# STM32H743 register map
File version: 2.4
CPU: CM7 r0p1, little endian, MPU, FPU, 4 interrupt priority bits
Registers are 32-bit, read-write, reset 0x0 unless marked. A register's access mark holds for its fields unless they carry their own. Offsets are from the block's base; [hi:lo] are bit positions; {n}, {i} and the like mark numbered series; 'fields as' and 'values as' point back to an identical list.

## HRTIM_TIMC — 高分辨率定时器：TIMC
Base 0x40017580
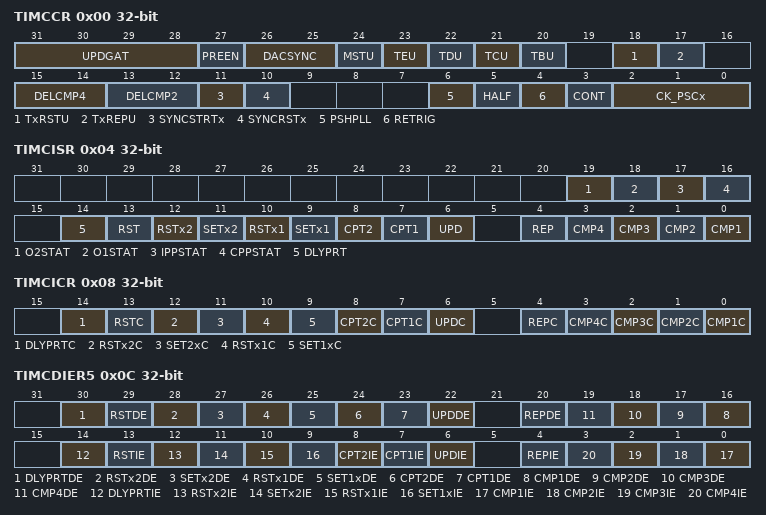
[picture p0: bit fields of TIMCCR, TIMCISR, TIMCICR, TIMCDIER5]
0x00 TIMCCR — TIMC 控制寄存器
  [31:28] UPDGAT — 更新门控
  [27] PREEN — 预装载使能
  [26:25] DACSYNC — DAC 同步
  [24] MSTU — 主定时器更新
  [23] TEU — 定时器 E 更新
  [22] TDU — 定时器 D 更新
  [21] TCU — 定时器 C 更新
  [20] TBU — 定时器 B 更新
  [18] TxRSTU — TIMC 复位更新
  [17] TxREPU — TIMC 重复更新
  [15:14] DELCMP4 — 延迟比较 4 模式
  [13:12] DELCMP2 — 延迟比较 2 模式
  [11] SYNCSTRTx — 同步启动 TIMC
  [10] SYNCRSTx — 同步复位 TIMC
  [6] PSHPLL — 推挽模式使能
  [5] HALF — 半模式使能
  [4] RETRIG — 可重触发模式
  [3] CONT — 连续模式
  [2:0] CK_PSCx — HRTIM TIMC 时钟预分频器
0x04 TIMCISR ro — TIMC 中断状态寄存器
  [19] O2STAT — 输出 2 状态
  [18] O1STAT — 输出 1 状态
  [17] IPPSTAT — 空闲推挽状态
  [16] CPPSTAT — 当前推挽状态
  [14] DLYPRT — 延迟保护标志
  [13] RST — 复位中断标志
  [12] RSTx2 — 输出 2 复位中断标志
  [11] SETx2 — 输出 2 置位中断标志
  [10] RSTx1 — 输出 1 复位中断标志
  [9] SETx1 — 输出 1 置位中断标志
  [8] CPT2 — 捕获 2 中断标志
  [7] CPT1 — 捕获 1 中断标志
  [6] UPD — 更新中断标志
  [4] REP — 重复中断标志
  [n-1] CMP{n} (n=1..4) — 比较 {n} 中断标志
0x08 TIMCICR wo — TIMC 中断清除寄存器
  [14] DLYPRTC — 延迟保护标志清除
  [13] RSTC — 复位中断标志清除
  [12] RSTx2C — 输出 2 复位标志清除
  [11] SET2xC — 输出 2 置位标志清除
  [10] RSTx1C — 输出 1 复位标志清除
  [9] SET1xC — 输出 1 置位标志清除
  [8] CPT2C — 捕获 2 中断标志清除
  [7] CPT1C — 捕获 1 中断标志清除
  [6] UPDC — 更新中断标志清除
  [4] REPC — 重复中断标志清除
  [n-1] CMP{n}C (n=1..4) — 比较 {n} 中断标志清除
0x0C TIMCDIER5 — TIMC DMA / 中断使能寄存器
  [30] DLYPRTDE — 延迟保护 DMA 使能
  [29] RSTDE — 复位 DMA 使能
  [28] RSTx2DE — 输出 2 复位 DMA 使能
  [27] SETx2DE — 输出 2 置位 DMA 使能
  [26] RSTx1DE — 输出 1 复位 DMA 使能
  [25] SET1xDE — 输出 1 置位 DMA 使能
  [24] CPT2DE — 捕获 2 DMA 使能
  [23] CPT1DE — 捕获 1 DMA 使能
  [22] UPDDE — 更新 DMA 使能
  [20] REPDE — 重复 DMA 使能
  [n+15] CMP{n}DE (n=1..4) — 比较 {n} DMA 使能
  [14] DLYPRTIE — 延迟保护中断使能
  [13] RSTIE — 复位中断使能
  [12] RSTx2IE — 输出 2 复位中断使能
  [11] SETx2IE — 输出 2 置位中断使能
  [10] RSTx1IE — 输出 1 复位中断使能
  [9] SET1xIE — 输出 1 置位中断使能
  [8] CPT2IE — 捕获 2 中断使能
  [7] CPT1IE — 捕获 1 中断使能
  [6] UPDIE — 更新中断使能
  [4] REPIE — 重复中断使能
  [n-1] CMP{n}IE (n=1..4) — 比较 {n} 中断使能
0x10 CNTCR — TIMC 计数器寄存器
  [15:0] CNTx — TIMC 计数器值
0x14 PERCR reset 0xFFFF — TIMC 周期寄存器
  [15:0] PERx — TIMC 周期值
0x18 REPCR — TIMC 重复寄存器
  [7:0] REPx — TIMC 重复计数器值
0x1C CMP1CR — TIMC 比较 1 寄存器
  [15:0] CMP1x — TIMC 比较 1 值
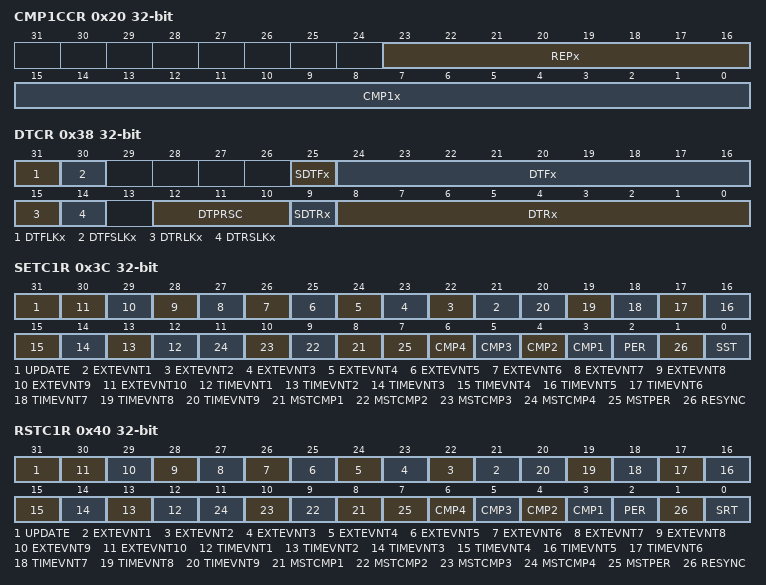
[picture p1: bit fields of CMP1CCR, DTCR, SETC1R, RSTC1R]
0x20 CMP1CCR — TIMC 比较 1 复合寄存器
  [23:16] REPx — TIMC 重复值（映射自 HRTIM_REPx 寄存器）
  [15:0] CMP1x — TIMC 比较 1 值
{0x1C+4i} CMP{i}CR (i=2..4) — TIMC 比较 {i} 寄存器
  [15:0] CMP{i}x — TIMC 比较 {i} 值
0x30 CPT1CR ro — TIMC 捕获 1 寄存器
  [15:0] CPT1x — TIMC 捕获 1 值
0x34 CPT2CR ro — TIMC 捕获 2 寄存器
  [15:0] CPT2x — TIMC 捕获 2 值
0x38 DTCR — TIMC 死区寄存器
  [31] DTFLKx — 下降沿死区锁定
  [30] DTFSLKx — 下降沿死区符号锁定
  [25] SDTFx — 下降沿死区符号值
  [24:16] DTFx — 下降沿死区值
  [15] DTRLKx — 上升沿死区锁定
  [14] DTRSLKx — 上升沿死区符号锁定
  [12:10] DTPRSC — 死区预分频器
  [9] SDTRx — 上升沿死区符号值
  [8:0] DTRx — 上升沿死区值
0x3C SETC1R — TIMC 输出 1 置位寄存器
  [31] UPDATE — 寄存器更新（预装载值传送到活跃寄存器）
  [n+20] EXTEVNT{n} (n=1..10) — 外部事件 {n}
  [n+11] TIMEVNT{n} (n=1..9) — 定时器事件 {n}
  [n+7] MSTCMP{n} (n=1..4) — 主比较 {n}
  [7] MSTPER — 主周期
  [n+2] CMP{n} (n=1..4) — 定时器 A 比较 {n}
  [2] PER — 定时器 A 周期
  [1] RESYNC — 定时器 A 再同步
  [0] SST — 软件置位触发
0x40 RSTC1R — TIMC 输出 1 复位寄存器
  [31] UPDATE — 寄存器更新（预装载值传送到活跃寄存器）
  [n+20] EXTEVNT{n} (n=1..10) — 外部事件 {n}
  [n+11] TIMEVNT{n} (n=1..9) — 定时器事件 {n}
  [n+7] MSTCMP{n} (n=1..4) — 主比较 {n}
  [7] MSTPER — 主周期
  [n+2] CMP{n} (n=1..4) — 定时器 A 比较 {n}
  [2] PER — 定时器 A 周期
  [1] RESYNC — 定时器 A 再同步
  [0] SRT — 软件复位触发
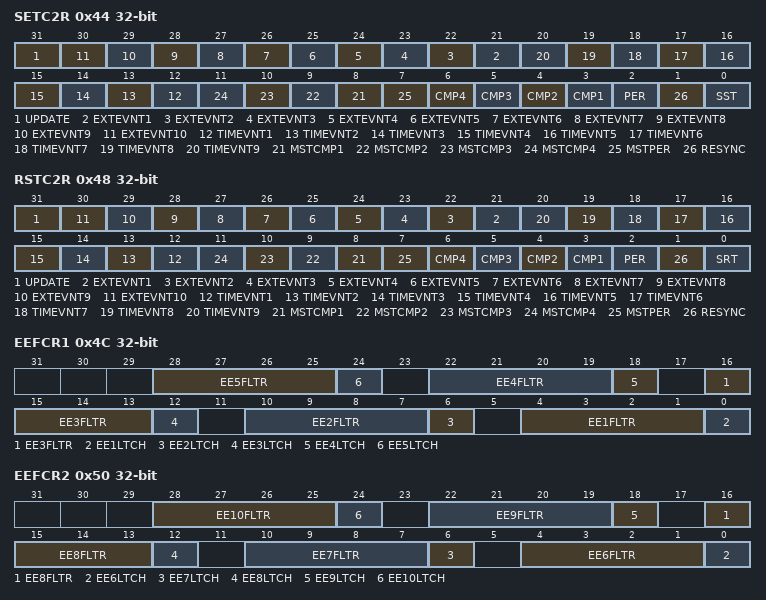
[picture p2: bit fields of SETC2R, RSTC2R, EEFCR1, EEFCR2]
0x44 SETC2R — TIMC 输出 2 置位寄存器
  fields as SETC1R
0x48 RSTC2R — TIMC 输出 2 复位寄存器
  fields as RSTC1R
0x4C EEFCR1 — TIMC 外部事件滤波寄存器 1
  [6n-2:6n-5] EE{n}FLTR (n=1..5) — 外部事件 {n} 滤波器
  [6n-6] EE{n}LTCH (n=1..5) — 外部事件 {n} 锁存
0x50 EEFCR2 — TIMC 外部事件滤波寄存器 2
  [6n-32:6n-35] EE{n}FLTR (n=6..10) — 外部事件 {n} 滤波器
  [6n-36] EE{n}LTCH (n=6..10) — 外部事件 {n} 锁存
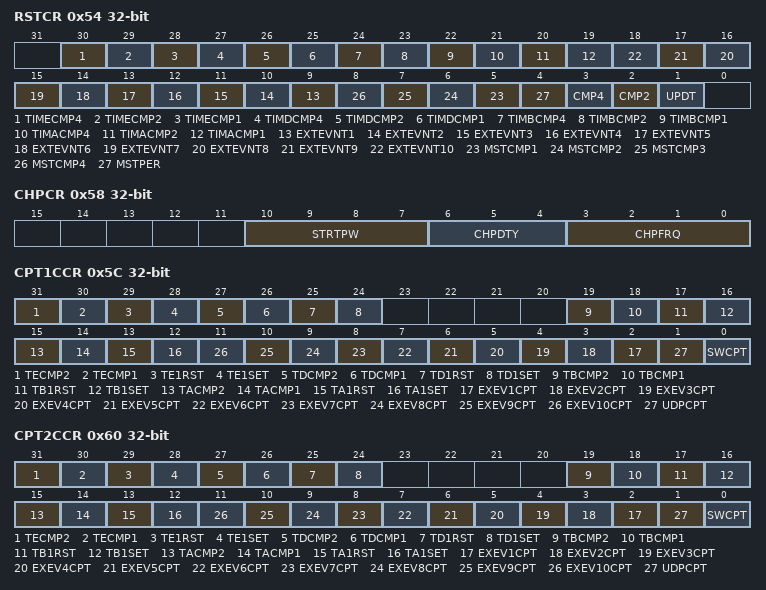
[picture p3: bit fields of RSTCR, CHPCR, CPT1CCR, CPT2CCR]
0x54 RSTCR — 定时器 A 复位寄存器
  [30] TIMECMP4 — 定时器 E 比较 4
  [29] TIMECMP2 — 定时器 E 比较 2
  [28] TIMECMP1 — 定时器 E 比较 1
  [27] TIMDCMP4 — 定时器 D 比较 4
  [26] TIMDCMP2 — 定时器 D 比较 2
  [25] TIMDCMP1 — 定时器 D 比较 1
  [24] TIMBCMP4 — 定时器 B 比较 4
  [23] TIMBCMP2 — 定时器 B 比较 2
  [22] TIMBCMP1 — 定时器 B 比较 1
  [21] TIMACMP4 — 定时器 A 比较 4
  [20] TIMACMP2 — 定时器 A 比较 2
  [19] TIMACMP1 — 定时器 A 比较 1
  [n+8] EXTEVNT{n} (n=1..10) — 外部事件 {n}
  [n+4] MSTCMP{n} (n=1..4) — 主比较 {n}
  [4] MSTPER — 主定时器周期
  [3] CMP4 — 定时器 A 比较 4 复位
  [2] CMP2 — 定时器 A 比较 2 复位
  [1] UPDT — 定时器 A 更新复位
0x58 CHPCR — TIMC 斩波寄存器
  [10:7] STRTPW — 斩波启动脉冲宽度
  [6:4] CHPDTY — TIMC 斩波占空比值
  [3:0] CHPFRQ — TIMC 载波频率值
0x5C CPT1CCR — TIMC 捕获 1 控制寄存器
  [31] TECMP2 — 定时器 E 比较 2
  [30] TECMP1 — 定时器 E 比较 1
  [29] TE1RST — 定时器 E 输出 1 复位
  [28] TE1SET — 定时器 E 输出 1 置位
  [27] TDCMP2 — 定时器 D 比较 2
  [26] TDCMP1 — 定时器 D 比较 1
  [25] TD1RST — 定时器 D 输出 1 复位
  [24] TD1SET — 定时器 D 输出 1 置位
  [19] TBCMP2 — 定时器 B 比较 2
  [18] TBCMP1 — 定时器 B 比较 1
  [17] TB1RST — 定时器 B 输出 1 复位
  [16] TB1SET — 定时器 B 输出 1 置位
  [15] TACMP2 — 定时器 A 比较 2
  [14] TACMP1 — 定时器 A 比较 1
  [13] TA1RST — 定时器 A 输出 1 复位
  [12] TA1SET — 定时器 A 输出 1 置位
  [n+1] EXEV{n}CPT (n=1..10) — 外部事件 {n} 捕获
  [1] UDPCPT — 更新捕获
  [0] SWCPT — 软件捕获
0x60 CPT2CCR — TIMC 捕获 2 控制寄存器
  fields as CPT1CCR
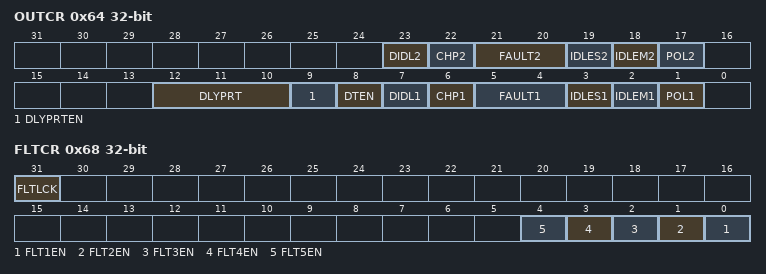
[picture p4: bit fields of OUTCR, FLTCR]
0x64 OUTCR — TIMC 输出寄存器
  [23] DIDL2 — 输出 2 突发模式空闲进入时的死区
  [22] CHP2 — 输出 2 斩波使能
  [21:20] FAULT2 — 输出 2 故障状态
  [19] IDLES2 — 输出 2 空闲状态
  [18] IDLEM2 — 输出 2 空闲模式
  [17] POL2 — 输出 2 极性
  [12:10] DLYPRT — 延迟保护
  [9] DLYPRTEN — 延迟保护使能
  [8] DTEN — 死区使能
  [7] DIDL1 — 输出 1 突发模式空闲进入时的死区
  [6] CHP1 — 输出 1 斩波使能
  [5:4] FAULT1 — 输出 1 故障状态
  [3] IDLES1 — 输出 1 空闲状态
  [2] IDLEM1 — 输出 1 空闲模式
  [1] POL1 — 输出 1 极性
0x68 FLTCR — TIMC 故障寄存器
  [31] FLTLCK — 故障源锁定
  [n-1] FLT{n}EN (n=1..5) — 故障 {n} 使能
